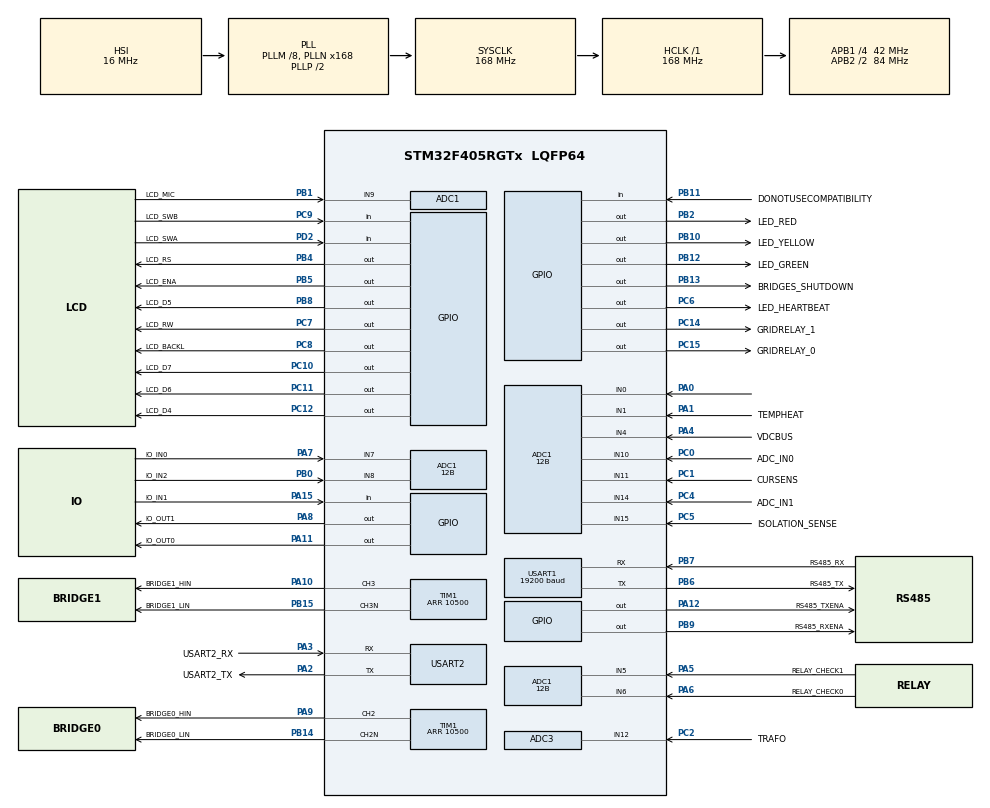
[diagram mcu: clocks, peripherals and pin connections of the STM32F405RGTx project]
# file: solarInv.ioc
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ADC1.Channel-0\#ChannelRegularConversion=ADC_CHANNEL_1
ADC1.Channel-3\#ChannelRegularConversion=ADC_CHANNEL_15
ADC1.Channel-4\#ChannelRegularConversion=ADC_CHANNEL_5
ADC1.Channel-5\#ChannelRegularConversion=ADC_CHANNEL_6
ADC1.Channel-8\#ChannelRegularConversion=ADC_CHANNEL_15
ADC1.Channel-9\#ChannelRegularConversion=ADC_CHANNEL_9
ADC1.ClockPrescaler=ADC_CLOCK_SYNC_PCLK_DIV4
ADC1.ContinuousConvMode=DISABLE
ADC1.DMAContinuousRequests=ENABLE
ADC1.DataAlign=ADC_DATAALIGN_RIGHT
ADC1.DiscontinuousConvMode=ENABLE
ADC1.EOCSelection=ADC_EOC_SEQ_CONV
ADC1.EnableAnalogWatchDog=false
ADC1.ExternalTrigConv=ADC_EXTERNALTRIGCONV_T1_CC1
ADC1.ExternalTrigConvEdge=ADC_EXTERNALTRIGCONVEDGE_RISING
ADC1.InjNumberOfConversion=0
ADC1.NbrOfConversion=5
ADC1.NbrOfConversionFlag=1
ADC1.NbrOfDiscConversion=1
ADC1.Rank-0\#ChannelRegularConversion=1
ADC1.Rank-3\#ChannelRegularConversion=4
ADC1.Rank-4\#ChannelRegularConversion=2
ADC1.Rank-5\#ChannelRegularConversion=3
ADC1.Rank-8\#ChannelRegularConversion=4
ADC1.Rank-9\#ChannelRegularConversion=5
ADC1.Resolution=ADC_RESOLUTION_12B
ADC1.SamplingTime-0\#ChannelRegularConversion=ADC_SAMPLETIME_3CYCLES
ADC1.SamplingTime-3\#ChannelRegularConversion=ADC_SAMPLETIME_3CYCLES
ADC1.SamplingTime-4\#ChannelRegularConversion=ADC_SAMPLETIME_3CYCLES
ADC1.SamplingTime-5\#ChannelRegularConversion=ADC_SAMPLETIME_3CYCLES
ADC1.SamplingTime-8\#ChannelRegularConversion=ADC_SAMPLETIME_3CYCLES
ADC1.SamplingTime-9\#ChannelRegularConversion=ADC_SAMPLETIME_3CYCLES
ADC1.ScanConvMode=ENABLE
ADC1.master=1
ADC2.Channel-0\#ChannelRegularConversion=ADC_CHANNEL_4
ADC2.Channel-1\#ChannelRegularConversion=ADC_CHANNEL_4
ADC2.ClockPrescaler=ADC_CLOCK_SYNC_PCLK_DIV4
ADC2.ContinuousConvMode=DISABLE
ADC2.DMAContinuousRequests=ENABLE
ADC2.DataAlign=ADC_DATAALIGN_RIGHT
ADC2.DiscontinuousConvMode=ENABLE
ADC2.EOCSelection=ADC_EOC_SEQ_CONV
ADC2.EnableAnalogWatchDog=false
ADC2.ExternalTrigConv=ADC_EXTERNALTRIGCONV_T1_CC1
ADC2.ExternalTrigConvEdge=ADC_EXTERNALTRIGCONVEDGE_RISING
ADC2.InjNumberOfConversion=0
ADC2.NbrOfConversion=2
ADC2.NbrOfConversionFlag=1
ADC2.NbrOfDiscConversion=1
ADC2.Rank-0\#ChannelRegularConversion=1
ADC2.Rank-1\#ChannelRegularConversion=2
ADC2.Resolution=ADC_RESOLUTION_12B
ADC2.SamplingTime-0\#ChannelRegularConversion=ADC_SAMPLETIME_3CYCLES
ADC2.SamplingTime-1\#ChannelRegularConversion=ADC_SAMPLETIME_3CYCLES
ADC2.ScanConvMode=ENABLE
ADC3.Channel-4\#ChannelRegularConversion=ADC_CHANNEL_11
ADC3.Channel-5\#ChannelRegularConversion=ADC_CHANNEL_12
ADC3.ContinuousConvMode=DISABLE
ADC3.DMAContinuousRequests=ENABLE
ADC3.DataAlign=ADC_DATAALIGN_RIGHT
ADC3.DiscontinuousConvMode=ENABLE
ADC3.EOCSelection=ADC_EOC_SINGLE_CONV
ADC3.EnableAnalogWatchDog=false
ADC3.ExternalTrigConv=ADC_EXTERNALTRIGCONV_T1_CC1
ADC3.ExternalTrigConvEdge=ADC_EXTERNALTRIGCONVEDGE_RISING
ADC3.InjNumberOfConversion=0
ADC3.NbrOfConversion=2
ADC3.NbrOfConversionFlag=1
ADC3.NbrOfDiscConversion=1
ADC3.Rank-4\#ChannelRegularConversion=1
ADC3.Rank-5\#ChannelRegularConversion=2
ADC3.Resolution=ADC_RESOLUTION_12B
ADC3.SamplingTime-4\#ChannelRegularConversion=ADC_SAMPLETIME_3CYCLES
ADC3.SamplingTime-5\#ChannelRegularConversion=ADC_SAMPLETIME_3CYCLES
ADC3.ScanConvMode=ENABLE
Dma.ADC1.4.Direction=DMA_PERIPH_TO_MEMORY
Dma.ADC1.4.FIFOMode=DMA_FIFOMODE_DISABLE
Dma.ADC1.4.Instance=DMA2_Stream0
Dma.ADC1.4.MemDataAlignment=DMA_MDATAALIGN_HALFWORD
Dma.ADC1.4.MemInc=DMA_MINC_ENABLE
Dma.ADC1.4.Mode=DMA_CIRCULAR
Dma.ADC1.4.PeriphDataAlignment=DMA_PDATAALIGN_HALFWORD
Dma.ADC1.4.PeriphInc=DMA_PINC_DISABLE
Dma.ADC1.4.Priority=DMA_PRIORITY_MEDIUM
Dma.ADC2.5.Direction=DMA_PERIPH_TO_MEMORY
Dma.ADC2.5.FIFOMode=DMA_FIFOMODE_DISABLE
Dma.ADC2.5.Instance=DMA2_Stream2
Dma.ADC2.5.MemDataAlignment=DMA_MDATAALIGN_HALFWORD
Dma.ADC2.5.MemInc=DMA_MINC_ENABLE
Dma.ADC2.5.Mode=DMA_CIRCULAR
Dma.ADC2.5.PeriphDataAlignment=DMA_PDATAALIGN_HALFWORD
Dma.ADC2.5.PeriphInc=DMA_PINC_DISABLE
Dma.ADC2.5.Priority=DMA_PRIORITY_MEDIUM
Dma.ADC3.1.Direction=DMA_PERIPH_TO_MEMORY
Dma.ADC3.1.FIFOMode=DMA_FIFOMODE_DISABLE
Dma.ADC3.1.Instance=DMA2_Stream1
Dma.ADC3.1.MemDataAlignment=DMA_MDATAALIGN_HALFWORD
Dma.ADC3.1.MemInc=DMA_MINC_ENABLE
Dma.ADC3.1.Mode=DMA_CIRCULAR
Dma.ADC3.1.PeriphDataAlignment=DMA_PDATAALIGN_HALFWORD
Dma.ADC3.1.PeriphInc=DMA_PINC_DISABLE
Dma.ADC3.1.Priority=DMA_PRIORITY_MEDIUM
Dma.MEMTOMEM.0.Direction=DMA_MEMORY_TO_MEMORY
Dma.MEMTOMEM.0.FIFOMode=DMA_FIFOMODE_ENABLE
Dma.MEMTOMEM.0.FIFOThreshold=DMA_FIFO_THRESHOLD_FULL
Dma.MEMTOMEM.0.Instance=DMA2_Stream4
Dma.MEMTOMEM.0.MemBurst=DMA_MBURST_SINGLE
Dma.MEMTOMEM.0.MemDataAlignment=DMA_MDATAALIGN_WORD
Dma.MEMTOMEM.0.MemInc=DMA_MINC_ENABLE
Dma.MEMTOMEM.0.Mode=DMA_NORMAL
Dma.MEMTOMEM.0.PeriphBurst=DMA_PBURST_SINGLE
Dma.MEMTOMEM.0.PeriphDataAlignment=DMA_PDATAALIGN_WORD
Dma.MEMTOMEM.0.PeriphInc=DMA_PINC_ENABLE
Dma.MEMTOMEM.0.Priority=DMA_PRIORITY_LOW
Dma.Request0=MEMTOMEM
Dma.Request1=ADC3
Dma.Request2=USART1_TX
Dma.Request3=USART1_RX
Dma.Request4=ADC1
Dma.Request5=ADC2
Dma.USART1_RX.3.Direction=DMA_PERIPH_TO_MEMORY
Dma.USART1_RX.3.FIFOMode=DMA_FIFOMODE_DISABLE
Dma.USART1_RX.3.Instance=DMA2_Stream5
Dma.USART1_RX.3.MemDataAlignment=DMA_MDATAALIGN_BYTE
Dma.USART1_RX.3.MemInc=DMA_MINC_ENABLE
Dma.USART1_RX.3.Mode=DMA_CIRCULAR
Dma.USART1_RX.3.PeriphDataAlignment=DMA_PDATAALIGN_BYTE
Dma.USART1_RX.3.PeriphInc=DMA_PINC_DISABLE
Dma.USART1_RX.3.Priority=DMA_PRIORITY_LOW
Dma.USART1_TX.2.Direction=DMA_MEMORY_TO_PERIPH
Dma.USART1_TX.2.FIFOMode=DMA_FIFOMODE_DISABLE
Dma.USART1_TX.2.Instance=DMA2_Stream7
Dma.USART1_TX.2.MemDataAlignment=DMA_MDATAALIGN_BYTE
Dma.USART1_TX.2.MemInc=DMA_MINC_ENABLE
Dma.USART1_TX.2.Mode=DMA_NORMAL
Dma.USART1_TX.2.PeriphDataAlignment=DMA_PDATAALIGN_BYTE
Dma.USART1_TX.2.PeriphInc=DMA_PINC_DISABLE
Dma.USART1_TX.2.Priority=DMA_PRIORITY_LOW
FREERTOS.INCLUDE_vTaskDelayUntil=1
FREERTOS.Tasks01=defaultTask,0,4192,StartDefaultTask,Default,NULL,Dynamic,NULL,NULL;commandThread,-2,4192,startCommandThread,As external,NULL,Dynamic,NULL,NULL
FREERTOS.configENABLE_BACKWARD_COMPATIBILITY=0
FREERTOS.configTOTAL_HEAP_SIZE=64000
FREERTOS.configUSE_COUNTING_SEMAPHORES=1
Mcu.Family=STM32F4
Mcu.Name=STM32F405RGTx
Mcu.Package=LQFP64
NVIC.DMA2_Stream0_IRQn=true\:5\:0\:false\:false\:true\:false\:true\:true
NVIC.DMA2_Stream1_IRQn=true\:5\:0\:true\:false\:true\:true\:true\:true
NVIC.DMA2_Stream2_IRQn=true\:5\:0\:false\:false\:true\:true\:true\:true
NVIC.DMA2_Stream4_IRQn=true\:5\:0\:false\:false\:true\:false\:true\:true
NVIC.DMA2_Stream5_IRQn=true\:5\:0\:false\:false\:true\:false\:true\:true
NVIC.DMA2_Stream7_IRQn=true\:5\:0\:true\:false\:true\:true\:true\:true
NVIC.FPU_IRQn=true\:5\:0\:false\:false\:true\:true\:false\:false
NVIC.PriorityGroup=NVIC_PRIORITYGROUP_4
NVIC.TIM8_UP_TIM13_IRQn=true\:0\:0\:false\:false\:true\:false\:true\:true
NVIC.TimeBase=TIM8_UP_TIM13_IRQn
NVIC.TimeBaseIP=TIM13
NVIC.USART1_IRQn=true\:5\:0\:true\:false\:true\:true\:true\:true
PA0-WKUP.Signal=ADCx_IN0
PA1.GPIO_Label=TEMPHEAT
PA1.Signal=ADCx_IN1
PA10.GPIO_Label=BRIDGE1_HIN
PA10.GPIO_Speed=GPIO_SPEED_FREQ_HIGH
PA10.Signal=S_TIM1_CH3
PA11.GPIO_Label=IO_OUT0
PA11.Signal=GPIO_Output
PA12.GPIO_Label=RS485_TXENA
PA12.Signal=GPIO_Output
PA13.Mode=Trace_Asynchronous_SW
PA13.Signal=SYS_JTMS-SWDIO
PA14.Mode=Trace_Asynchronous_SW
PA14.Signal=SYS_JTCK-SWCLK
PA15.GPIO_Label=IO_IN1
PA15.GPIO_PuPd=GPIO_NOPULL
PA15.Signal=GPIO_Input
PA2.GPIO_Label=USART2_TX
PA2.GPIO_Speed=GPIO_SPEED_FREQ_HIGH
PA2.Mode=Asynchronous
PA2.Signal=USART2_TX
PA3.GPIO_Label=USART2_RX
PA3.GPIO_Speed=GPIO_SPEED_FREQ_HIGH
PA3.Mode=Asynchronous
PA3.Signal=USART2_RX
PA4.GPIO_Label=VDCBUS
PA4.Signal=ADCx_IN4
PA5.GPIO_Label=RELAY_CHECK1
PA5.Signal=ADCx_IN5
PA6.GPIO_Label=RELAY_CHECK0
PA6.Signal=ADCx_IN6
PA7.GPIO_Label=IO_IN0
PA7.Signal=ADCx_IN7
PA8.GPIO_Label=IO_OUT1
PA8.Signal=GPIO_Output
PA9.GPIO_Label=BRIDGE0_HIN
PA9.GPIO_Speed=GPIO_SPEED_FREQ_HIGH
PA9.Signal=S_TIM1_CH2
PB0.GPIO_Label=IO_IN2
PB0.Signal=ADCx_IN8
PB1.GPIO_Label=LCD_MIC
PB1.Signal=ADCx_IN9
PB10.GPIO_Label=LED_YELLOW
PB10.Signal=GPIO_Output
PB11.GPIO_Label=DONOTUSECOMPATIBILITY
PB11.GPIO_Mode=GPIO_MODE_INPUT
PB11.GPIO_PuPd=GPIO_NOPULL
PB11.Signal=GPIO_Input
PB12.GPIO_Label=LED_GREEN
PB12.Signal=GPIO_Output
PB13.GPIO_Label=BRIDGES_SHUTDOWN
PB13.GPIO_Speed=GPIO_SPEED_FREQ_MEDIUM
PB13.PinState=GPIO_PIN_SET
PB13.Signal=GPIO_Output
PB14.GPIO_Label=BRIDGE0_LIN
PB14.GPIO_ModeDefaultPP=GPIO_MODE_AF_PP
PB14.GPIO_PuPd=GPIO_NOPULL
PB14.GPIO_Speed=GPIO_SPEED_FREQ_HIGH
PB14.Mode=PWM Generation2 CH2 CH2N
PB14.Signal=TIM1_CH2N
PB15.GPIO_Label=BRIDGE1_LIN
PB15.GPIO_ModeDefaultPP=GPIO_MODE_AF_PP
PB15.GPIO_PuPd=GPIO_NOPULL
PB15.GPIO_Speed=GPIO_SPEED_FREQ_HIGH
PB15.Mode=PWM Generation3 CH3 CH3N
PB15.Signal=TIM1_CH3N
PB2.GPIO_Label=LED_RED
PB2.Signal=GPIO_Output
PB3.Mode=Trace_Asynchronous_SW
PB3.Signal=SYS_JTDO-SWO
PB4.GPIO_Label=LCD_RS
PB4.Signal=GPIO_Output
PB5.GPIO_Label=LCD_ENA
PB5.GPIO_ModeDefaultOutputPP=GPIO_MODE_OUTPUT_PP
PB5.GPIO_PuPd=GPIO_NOPULL
PB5.GPIO_Speed=GPIO_SPEED_FREQ_LOW
PB5.PinState=GPIO_PIN_RESET
PB5.Signal=GPIO_Output
PB6.GPIO_Label=RS485_TX
PB6.GPIO_Speed=GPIO_SPEED_FREQ_HIGH
PB6.Mode=Asynchronous
PB6.Signal=USART1_TX
PB7.GPIO_Label=RS485_RX
PB7.GPIO_Speed=GPIO_SPEED_FREQ_HIGH
PB7.Mode=Asynchronous
PB7.Signal=USART1_RX
PB8.GPIO_Label=LCD_D5
PB8.Signal=GPIO_Output
PB9.GPIO_Label=RS485_RXENA
PB9.Signal=GPIO_Output
PC0.GPIO_Label=ADC_IN0
PC0.Signal=ADCx_IN10
PC1.GPIO_Label=CURSENS
PC1.GPIO_Mode=GPIO_MODE_ANALOG
PC1.GPIO_PuPd=GPIO_NOPULL
PC1.Signal=ADCx_IN11
PC10.GPIO_Label=LCD_D7
PC10.Signal=GPIO_Output
PC11.GPIO_Label=LCD_D6
PC11.Signal=GPIO_Output
PC12.GPIO_Label=LCD_D4
PC12.Signal=GPIO_Output
PC14-OSC32_IN.GPIO_Label=GRIDRELAY_1
PC14-OSC32_IN.Signal=GPIO_Output
PC15-OSC32_OUT.GPIO_Label=GRIDRELAY_0
PC15-OSC32_OUT.Signal=GPIO_Output
PC2.GPIO_Label=TRAFO
PC2.GPIO_Mode=GPIO_MODE_ANALOG
PC2.GPIO_PuPd=GPIO_NOPULL
PC2.Signal=ADCx_IN12
PC4.GPIO_Label=ADC_IN1
PC4.Signal=ADCx_IN14
PC5.GPIO_Label=ISOLATION_SENSE
PC5.Signal=ADCx_IN15
PC6.GPIO_Label=LED_HEARTBEAT
PC6.Signal=GPIO_Output
PC7.GPIO_Label=LCD_RW
PC7.Signal=GPIO_Output
PC8.GPIO_Label=LCD_BACKL
PC8.Signal=GPIO_Output
PC9.GPIO_Label=LCD_SWB
PC9.GPIO_PuPd=GPIO_PULLUP
PC9.Signal=GPIO_Input
PD2.GPIO_Label=LCD_SWA
PD2.GPIO_PuPd=GPIO_PULLUP
PD2.Signal=GPIO_Input
ProjectManager.HeapSize=0x400
ProjectManager.StackSize=0x800
ProjectManager.TargetToolchain=STM32CubeIDE
RCC.48MHZClocksFreq_Value=48000000
RCC.AHBFreq_Value=168000000
RCC.APB1CLKDivider=RCC_HCLK_DIV4
RCC.APB1Freq_Value=42000000
RCC.APB1TimFreq_Value=84000000
RCC.APB2CLKDivider=RCC_HCLK_DIV2
RCC.APB2Freq_Value=84000000
RCC.APB2TimFreq_Value=168000000
RCC.CortexFreq_Value=168000000
RCC.HCLKFreq_Value=168000000
RCC.HSE_VALUE=8000000
RCC.HSI_VALUE=16000000
RCC.LSE_VALUE=32768
RCC.PLLM=8
RCC.PLLN=168
RCC.PLLQ=7
RCC.SYSCLKFreq_VALUE=168000000
RCC.SYSCLKSource=RCC_SYSCLKSOURCE_PLLCLK
RCC.VCOOutputFreq_Value=336000000
SH.ADCx_IN0.0=ADC1_IN0,IN0
SH.ADCx_IN1.0=ADC1_IN1,IN1
SH.ADCx_IN10.0=ADC1_IN10,IN10
SH.ADCx_IN11.0=ADC1_IN11,IN11
SH.ADCx_IN11.1=ADC3_IN11,IN11
SH.ADCx_IN11.2=ADC2_IN11,IN11
SH.ADCx_IN12.0=ADC3_IN12,IN12
SH.ADCx_IN12.1=ADC1_IN12,IN12
SH.ADCx_IN12.2=ADC2_IN12,IN12
SH.ADCx_IN14.0=ADC1_IN14,IN14
SH.ADCx_IN15.0=ADC1_IN15,IN15
SH.ADCx_IN4.0=ADC1_IN4,IN4
SH.ADCx_IN4.1=ADC2_IN4,IN4
SH.ADCx_IN5.0=ADC1_IN5,IN5
SH.ADCx_IN6.0=ADC1_IN6,IN6
SH.ADCx_IN7.0=ADC1_IN7,IN7
SH.ADCx_IN8.0=ADC1_IN8,IN8
SH.ADCx_IN9.0=ADC1_IN9,IN9
SH.ADCx_IN9.1=ADC2_IN9,IN9
SH.S_TIM1_CH2.0=TIM1_CH2,PWM Generation2 CH2 CH2N
SH.S_TIM1_CH3.0=TIM1_CH3,PWM Generation3 CH3 CH3N
TIM1.AutomaticOutput=TIM_AUTOMATICOUTPUT_ENABLE
TIM1.BreakPolarity=TIM_BREAKPOLARITY_LOW
TIM1.BreakState=TIM_BREAK_DISABLE
TIM1.Channel-PWM\ Generation2\ CH2\ CH2N=TIM_CHANNEL_2
TIM1.Channel-PWM\ Generation3\ CH3\ CH3N=TIM_CHANNEL_3
TIM1.CounterMode=TIM_COUNTERMODE_UP
TIM1.DeadTime=30
TIM1.OCNPolarity_2=TIM_OCNPOLARITY_HIGH
TIM1.OCNPolarity_3=TIM_OCNPOLARITY_HIGH
TIM1.OffStateIDLEMode=TIM_OSSI_ENABLE
TIM1.OffStateRunMode=TIM_OSSR_ENABLE
TIM1.Period=10500
TIM2.AutoReloadPreload=TIM_AUTORELOAD_PRELOAD_ENABLE
TIM2.Period=16000
TIM2.Prescaler=5250
TIM4.AutoReloadPreload=TIM_AUTORELOAD_PRELOAD_DISABLE
TIM4.Period=3281
TIM4.Prescaler=1280
USART1.BaudRate=19200
USART1.VirtualMode=VM_ASYNC
USART2.VirtualMode=VM_ASYNC
VP_ADC1_Vref_Input.Mode=IN-Vrefint
VP_FREERTOS_VS_CMSIS_V1.Mode=CMSIS_V1
VP_SYS_VS_tim13.Mode=TIM13
VP_TIM1_VS_ClockSourceINT.Mode=Internal
VP_TIM2_VS_ClockSourceINT.Mode=Internal
VP_TIM4_VS_ClockSourceINT.Mode=Internal
board=solarInv

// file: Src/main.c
/* USER CODE BEGIN Header */
/**
  ******************************************************************************
  * @file           : main.c
  * @brief          : Main program body
  ******************************************************************************
  * @attention
  *
  * <h2><center>&copy; Copyright (c) 2022 STMicroelectronics.
  * All rights reserved.</center></h2>
  *
  * This software component is licensed by ST under Ultimate Liberty license
  * SLA0044, the "License"; You may not use this file except in compliance with
  * the License. You may obtain a copy of the License at:
  *                             www.st.com/SLA0044
  *
  ******************************************************************************
  */
/* USER CODE END Header */
#include "main.h"
#include "cmsis_os.h"

/* USER CODE BEGIN Includes */
#include "HardwareDefines.h"
#include "controlLoop.h"
/* USER CODE END Includes */

ADC_HandleTypeDef hadc1;
ADC_HandleTypeDef hadc2;
ADC_HandleTypeDef hadc3;
DMA_HandleTypeDef hdma_adc1;
DMA_HandleTypeDef hdma_adc2;
DMA_HandleTypeDef hdma_adc3;

TIM_HandleTypeDef htim1;
TIM_HandleTypeDef htim2;
TIM_HandleTypeDef htim4;

UART_HandleTypeDef huart1;
UART_HandleTypeDef huart2;
DMA_HandleTypeDef hdma_usart1_tx;
DMA_HandleTypeDef hdma_usart1_rx;

DMA_HandleTypeDef hdma_memtomem_dma2_stream4;
osThreadId defaultTaskHandle;
osThreadId commandThreadHandle;

void SystemClock_Config(void);
static void MX_GPIO_Init(void);
static void MX_DMA_Init(void);
static void MX_ADC1_Init(void);
static void MX_ADC2_Init(void);
static void MX_ADC3_Init(void);
static void MX_TIM1_Init(void);
static void MX_TIM4_Init(void);
static void MX_USART1_UART_Init(void);
static void MX_USART2_UART_Init(void);
static void MX_TIM2_Init(void);
void StartDefaultTask(void const * argument);
extern void startCommandThread(void const * argument);

int main(void)
{

  /* MCU Configuration--------------------------------------------------------*/

  /* Reset of all peripherals, Initializes the Flash interface and the Systick. */
  HAL_Init();

  /* Configure the system clock */
  SystemClock_Config();

  /* Initialize all configured peripherals */
  MX_GPIO_Init();
  MX_DMA_Init();
  MX_ADC1_Init();
  MX_ADC2_Init();
  MX_ADC3_Init();
  MX_TIM1_Init();
  MX_TIM4_Init();
  MX_USART1_UART_Init();
  MX_USART2_UART_Init();
  MX_TIM2_Init();

  /* Create the thread(s) */
  /* definition and creation of defaultTask */
  osThreadDef(defaultTask, StartDefaultTask, osPriorityNormal, 0, 4192);
  defaultTaskHandle = osThreadCreate(osThread(defaultTask), NULL);

  /* definition and creation of commandThread */
  osThreadDef(commandThread, startCommandThread, osPriorityLow, 0, 4192);
  commandThreadHandle = osThreadCreate(osThread(commandThread), NULL);

  /* Start scheduler */
  osKernelStart();

  /* We should never get here as control is now taken by the scheduler */
  /* Infinite loop */
  while (1)
  {

  }
}

void SystemClock_Config(void)
{
  RCC_OscInitTypeDef RCC_OscInitStruct = {0};
  RCC_ClkInitTypeDef RCC_ClkInitStruct = {0};

  /** Configure the main internal regulator output voltage
  */
  __HAL_RCC_PWR_CLK_ENABLE();
  __HAL_PWR_VOLTAGESCALING_CONFIG(PWR_REGULATOR_VOLTAGE_SCALE1);
  /** Initializes the RCC Oscillators according to the specified parameters
  * in the RCC_OscInitTypeDef structure.
  */
  RCC_OscInitStruct.OscillatorType = RCC_OSCILLATORTYPE_HSI;
  RCC_OscInitStruct.HSIState = RCC_HSI_ON;
  RCC_OscInitStruct.HSICalibrationValue = RCC_HSICALIBRATION_DEFAULT;
  RCC_OscInitStruct.PLL.PLLState = RCC_PLL_ON;
  RCC_OscInitStruct.PLL.PLLSource = RCC_PLLSOURCE_HSI;
  RCC_OscInitStruct.PLL.PLLM = 8;
  RCC_OscInitStruct.PLL.PLLN = 168;
  RCC_OscInitStruct.PLL.PLLP = RCC_PLLP_DIV2;
  RCC_OscInitStruct.PLL.PLLQ = 7;
  if (HAL_RCC_OscConfig(&RCC_OscInitStruct) != HAL_OK)
  {
    Error_Handler();
  }
  /** Initializes the CPU, AHB and APB buses clocks
  */
  RCC_ClkInitStruct.ClockType = RCC_CLOCKTYPE_HCLK|RCC_CLOCKTYPE_SYSCLK
                              |RCC_CLOCKTYPE_PCLK1|RCC_CLOCKTYPE_PCLK2;
  RCC_ClkInitStruct.SYSCLKSource = RCC_SYSCLKSOURCE_PLLCLK;
  RCC_ClkInitStruct.AHBCLKDivider = RCC_SYSCLK_DIV1;
  RCC_ClkInitStruct.APB1CLKDivider = RCC_HCLK_DIV4;
  RCC_ClkInitStruct.APB2CLKDivider = RCC_HCLK_DIV2;

  if (HAL_RCC_ClockConfig(&RCC_ClkInitStruct, FLASH_LATENCY_5) != HAL_OK)
  {
    Error_Handler();
  }
}

static void MX_ADC1_Init(void)
{

  ADC_ChannelConfTypeDef sConfig = {0};

  /** Configure the global features of the ADC (Clock, Resolution, Data Alignment and number of conversion)
  */
  hadc1.Instance = ADC1;
  hadc1.Init.ClockPrescaler = ADC_CLOCK_SYNC_PCLK_DIV4;
  hadc1.Init.Resolution = ADC_RESOLUTION_12B;
  hadc1.Init.ScanConvMode = ENABLE;
  hadc1.Init.ContinuousConvMode = DISABLE;
  hadc1.Init.DiscontinuousConvMode = ENABLE;
  hadc1.Init.NbrOfDiscConversion = 1;
  hadc1.Init.ExternalTrigConvEdge = ADC_EXTERNALTRIGCONVEDGE_RISING;
  hadc1.Init.ExternalTrigConv = ADC_EXTERNALTRIGCONV_T1_CC1;
  hadc1.Init.DataAlign = ADC_DATAALIGN_RIGHT;
  hadc1.Init.NbrOfConversion = 5;
  hadc1.Init.DMAContinuousRequests = ENABLE;
  hadc1.Init.EOCSelection = ADC_EOC_SEQ_CONV;
  if (HAL_ADC_Init(&hadc1) != HAL_OK)
  {
    Error_Handler();
  }
  /** Configure for the selected ADC regular channel its corresponding rank in the sequencer and its sample time.
  */
  sConfig.Channel = ADC_CHANNEL_1;
  sConfig.Rank = 1;
  sConfig.SamplingTime = ADC_SAMPLETIME_3CYCLES;
  if (HAL_ADC_ConfigChannel(&hadc1, &sConfig) != HAL_OK)
  {
    Error_Handler();
  }
  /** Configure for the selected ADC regular channel its corresponding rank in the sequencer and its sample time.
  */
  sConfig.Channel = ADC_CHANNEL_15;
  sConfig.Rank = 4;
  if (HAL_ADC_ConfigChannel(&hadc1, &sConfig) != HAL_OK)
  {
    Error_Handler();
  }
  /** Configure for the selected ADC regular channel its corresponding rank in the sequencer and its sample time.
  */
  sConfig.Channel = ADC_CHANNEL_5;
  sConfig.Rank = 2;
  if (HAL_ADC_ConfigChannel(&hadc1, &sConfig) != HAL_OK)
  {
    Error_Handler();
  }
  /** Configure for the selected ADC regular channel its corresponding rank in the sequencer and its sample time.
  */
  sConfig.Channel = ADC_CHANNEL_6;
  sConfig.Rank = 3;
  if (HAL_ADC_ConfigChannel(&hadc1, &sConfig) != HAL_OK)
  {
    Error_Handler();
  }
  /** Configure for the selected ADC regular channel its corresponding rank in the sequencer and its sample time.
  */
  sConfig.Channel = ADC_CHANNEL_9;
  sConfig.Rank = 5;
  if (HAL_ADC_ConfigChannel(&hadc1, &sConfig) != HAL_OK)
  {
    Error_Handler();
  }

}

static void MX_ADC2_Init(void)
{

  ADC_ChannelConfTypeDef sConfig = {0};

  /** Configure the global features of the ADC (Clock, Resolution, Data Alignment and number of conversion)
  */
  hadc2.Instance = ADC2;
  hadc2.Init.ClockPrescaler = ADC_CLOCK_SYNC_PCLK_DIV4;
  hadc2.Init.Resolution = ADC_RESOLUTION_12B;
  hadc2.Init.ScanConvMode = ENABLE;
  hadc2.Init.ContinuousConvMode = DISABLE;
  hadc2.Init.DiscontinuousConvMode = ENABLE;
  hadc2.Init.NbrOfDiscConversion = 1;
  hadc2.Init.ExternalTrigConvEdge = ADC_EXTERNALTRIGCONVEDGE_RISING;
  hadc2.Init.ExternalTrigConv = ADC_EXTERNALTRIGCONV_T1_CC1;
  hadc2.Init.DataAlign = ADC_DATAALIGN_RIGHT;
  hadc2.Init.NbrOfConversion = 2;
  hadc2.Init.DMAContinuousRequests = ENABLE;
  hadc2.Init.EOCSelection = ADC_EOC_SEQ_CONV;
  if (HAL_ADC_Init(&hadc2) != HAL_OK)
  {
    Error_Handler();
  }
  /** Configure for the selected ADC regular channel its corresponding rank in the sequencer and its sample time.
  */
  sConfig.Channel = ADC_CHANNEL_4;
  sConfig.Rank = 1;
  sConfig.SamplingTime = ADC_SAMPLETIME_3CYCLES;
  if (HAL_ADC_ConfigChannel(&hadc2, &sConfig) != HAL_OK)
  {
    Error_Handler();
  }
  /** Configure for the selected ADC regular channel its corresponding rank in the sequencer and its sample time.
  */
  sConfig.Rank = 2;
  if (HAL_ADC_ConfigChannel(&hadc2, &sConfig) != HAL_OK)
  {
    Error_Handler();
  }

}

static void MX_ADC3_Init(void)
{

  ADC_ChannelConfTypeDef sConfig = {0};

  /** Configure the global features of the ADC (Clock, Resolution, Data Alignment and number of conversion)
  */
  hadc3.Instance = ADC3;
  hadc3.Init.ClockPrescaler = ADC_CLOCK_SYNC_PCLK_DIV4;
  hadc3.Init.Resolution = ADC_RESOLUTION_12B;
  hadc3.Init.ScanConvMode = ENABLE;
  hadc3.Init.ContinuousConvMode = DISABLE;
  hadc3.Init.DiscontinuousConvMode = ENABLE;
  hadc3.Init.NbrOfDiscConversion = 1;
  hadc3.Init.ExternalTrigConvEdge = ADC_EXTERNALTRIGCONVEDGE_RISING;
  hadc3.Init.ExternalTrigConv = ADC_EXTERNALTRIGCONV_T1_CC1;
  hadc3.Init.DataAlign = ADC_DATAALIGN_RIGHT;
  hadc3.Init.NbrOfConversion = 2;
  hadc3.Init.DMAContinuousRequests = ENABLE;
  hadc3.Init.EOCSelection = ADC_EOC_SINGLE_CONV;
  if (HAL_ADC_Init(&hadc3) != HAL_OK)
  {
    Error_Handler();
  }
  /** Configure for the selected ADC regular channel its corresponding rank in the sequencer and its sample time.
  */
  sConfig.Channel = ADC_CHANNEL_11;
  sConfig.Rank = 1;
  sConfig.SamplingTime = ADC_SAMPLETIME_3CYCLES;
  if (HAL_ADC_ConfigChannel(&hadc3, &sConfig) != HAL_OK)
  {
    Error_Handler();
  }
  /** Configure for the selected ADC regular channel its corresponding rank in the sequencer and its sample time.
  */
  sConfig.Channel = ADC_CHANNEL_12;
  sConfig.Rank = 2;
  if (HAL_ADC_ConfigChannel(&hadc3, &sConfig) != HAL_OK)
  {
    Error_Handler();
  }

}

static void MX_TIM1_Init(void)
{

  TIM_ClockConfigTypeDef sClockSourceConfig = {0};
  TIM_MasterConfigTypeDef sMasterConfig = {0};
  TIM_OC_InitTypeDef sConfigOC = {0};
  TIM_BreakDeadTimeConfigTypeDef sBreakDeadTimeConfig = {0};

  htim1.Instance = TIM1;
  htim1.Init.Prescaler = 0;
  htim1.Init.CounterMode = TIM_COUNTERMODE_UP;
  htim1.Init.Period = 10500;
  htim1.Init.ClockDivision = TIM_CLOCKDIVISION_DIV1;
  htim1.Init.RepetitionCounter = 0;
  htim1.Init.AutoReloadPreload = TIM_AUTORELOAD_PRELOAD_DISABLE;
  if (HAL_TIM_Base_Init(&htim1) != HAL_OK)
  {
    Error_Handler();
  }
  sClockSourceConfig.ClockSource = TIM_CLOCKSOURCE_INTERNAL;
  if (HAL_TIM_ConfigClockSource(&htim1, &sClockSourceConfig) != HAL_OK)
  {
    Error_Handler();
  }
  if (HAL_TIM_PWM_Init(&htim1) != HAL_OK)
  {
    Error_Handler();
  }
  sMasterConfig.MasterOutputTrigger = TIM_TRGO_RESET;
  sMasterConfig.MasterSlaveMode = TIM_MASTERSLAVEMODE_DISABLE;
  if (HAL_TIMEx_MasterConfigSynchronization(&htim1, &sMasterConfig) != HAL_OK)
  {
    Error_Handler();
  }
  sConfigOC.OCMode = TIM_OCMODE_PWM1;
  sConfigOC.Pulse = 0;
  sConfigOC.OCPolarity = TIM_OCPOLARITY_HIGH;
  sConfigOC.OCNPolarity = TIM_OCNPOLARITY_HIGH;
  sConfigOC.OCFastMode = TIM_OCFAST_DISABLE;
  sConfigOC.OCIdleState = TIM_OCIDLESTATE_RESET;
  sConfigOC.OCNIdleState = TIM_OCNIDLESTATE_RESET;
  if (HAL_TIM_PWM_ConfigChannel(&htim1, &sConfigOC, TIM_CHANNEL_2) != HAL_OK)
  {
    Error_Handler();
  }
  if (HAL_TIM_PWM_ConfigChannel(&htim1, &sConfigOC, TIM_CHANNEL_3) != HAL_OK)
  {
    Error_Handler();
  }
  sBreakDeadTimeConfig.OffStateRunMode = TIM_OSSR_ENABLE;
  sBreakDeadTimeConfig.OffStateIDLEMode = TIM_OSSI_ENABLE;
  sBreakDeadTimeConfig.LockLevel = TIM_LOCKLEVEL_OFF;
  sBreakDeadTimeConfig.DeadTime = 0;
  sBreakDeadTimeConfig.BreakState = TIM_BREAK_DISABLE;
  sBreakDeadTimeConfig.BreakPolarity = TIM_BREAKPOLARITY_LOW;
  sBreakDeadTimeConfig.AutomaticOutput = TIM_AUTOMATICOUTPUT_ENABLE;
  if (HAL_TIMEx_ConfigBreakDeadTime(&htim1, &sBreakDeadTimeConfig) != HAL_OK)
  {
    Error_Handler();
  }
  HAL_TIM_MspPostInit(&htim1);

}

static void MX_TIM2_Init(void)
{

  TIM_ClockConfigTypeDef sClockSourceConfig = {0};
  TIM_MasterConfigTypeDef sMasterConfig = {0};

  htim2.Instance = TIM2;
  htim2.Init.Prescaler = 5250;
  htim2.Init.CounterMode = TIM_COUNTERMODE_UP;
  htim2.Init.Period = 16000;
  htim2.Init.ClockDivision = TIM_CLOCKDIVISION_DIV1;
  htim2.Init.AutoReloadPreload = TIM_AUTORELOAD_PRELOAD_ENABLE;
  if (HAL_TIM_Base_Init(&htim2) != HAL_OK)
  {
    Error_Handler();
  }
  sClockSourceConfig.ClockSource = TIM_CLOCKSOURCE_INTERNAL;
  if (HAL_TIM_ConfigClockSource(&htim2, &sClockSourceConfig) != HAL_OK)
  {
    Error_Handler();
  }
  sMasterConfig.MasterOutputTrigger = TIM_TRGO_RESET;
  sMasterConfig.MasterSlaveMode = TIM_MASTERSLAVEMODE_DISABLE;
  if (HAL_TIMEx_MasterConfigSynchronization(&htim2, &sMasterConfig) != HAL_OK)
  {
    Error_Handler();
  }

}

static void MX_TIM4_Init(void)
{

  TIM_ClockConfigTypeDef sClockSourceConfig = {0};
  TIM_MasterConfigTypeDef sMasterConfig = {0};

  htim4.Instance = TIM4;
  htim4.Init.Prescaler = 1280;
  htim4.Init.CounterMode = TIM_COUNTERMODE_UP;
  htim4.Init.Period = 3281;
  htim4.Init.ClockDivision = TIM_CLOCKDIVISION_DIV1;
  htim4.Init.AutoReloadPreload = TIM_AUTORELOAD_PRELOAD_DISABLE;
  if (HAL_TIM_Base_Init(&htim4) != HAL_OK)
  {
    Error_Handler();
  }
  sClockSourceConfig.ClockSource = TIM_CLOCKSOURCE_INTERNAL;
  if (HAL_TIM_ConfigClockSource(&htim4, &sClockSourceConfig) != HAL_OK)
  {
    Error_Handler();
  }
  sMasterConfig.MasterOutputTrigger = TIM_TRGO_RESET;
  sMasterConfig.MasterSlaveMode = TIM_MASTERSLAVEMODE_DISABLE;
  if (HAL_TIMEx_MasterConfigSynchronization(&htim4, &sMasterConfig) != HAL_OK)
  {
    Error_Handler();
  }

}

static void MX_USART1_UART_Init(void)
{

  huart1.Instance = USART1;
  huart1.Init.BaudRate = 19200;
  huart1.Init.WordLength = UART_WORDLENGTH_8B;
  huart1.Init.StopBits = UART_STOPBITS_1;
  huart1.Init.Parity = UART_PARITY_NONE;
  huart1.Init.Mode = UART_MODE_TX_RX;
  huart1.Init.HwFlowCtl = UART_HWCONTROL_NONE;
  huart1.Init.OverSampling = UART_OVERSAMPLING_16;
  if (HAL_UART_Init(&huart1) != HAL_OK)
  {
    Error_Handler();
  }

}

static void MX_USART2_UART_Init(void)
{

  huart2.Instance = USART2;
  huart2.Init.BaudRate = 115200;
  huart2.Init.WordLength = UART_WORDLENGTH_8B;
  huart2.Init.StopBits = UART_STOPBITS_1;
  huart2.Init.Parity = UART_PARITY_NONE;
  huart2.Init.Mode = UART_MODE_TX_RX;
  huart2.Init.HwFlowCtl = UART_HWCONTROL_NONE;
  huart2.Init.OverSampling = UART_OVERSAMPLING_16;
  if (HAL_UART_Init(&huart2) != HAL_OK)
  {
    Error_Handler();
  }

}

static void MX_DMA_Init(void)
{

  /* DMA controller clock enable */
  __HAL_RCC_DMA2_CLK_ENABLE();

  /* Configure DMA request hdma_memtomem_dma2_stream4 on DMA2_Stream4 */
  hdma_memtomem_dma2_stream4.Instance = DMA2_Stream4;
  hdma_memtomem_dma2_stream4.Init.Channel = DMA_CHANNEL_0;
  hdma_memtomem_dma2_stream4.Init.Direction = DMA_MEMORY_TO_MEMORY;
  hdma_memtomem_dma2_stream4.Init.PeriphInc = DMA_PINC_ENABLE;
  hdma_memtomem_dma2_stream4.Init.MemInc = DMA_MINC_ENABLE;
  hdma_memtomem_dma2_stream4.Init.PeriphDataAlignment = DMA_PDATAALIGN_WORD;
  hdma_memtomem_dma2_stream4.Init.MemDataAlignment = DMA_MDATAALIGN_WORD;
  hdma_memtomem_dma2_stream4.Init.Mode = DMA_NORMAL;
  hdma_memtomem_dma2_stream4.Init.Priority = DMA_PRIORITY_LOW;
  hdma_memtomem_dma2_stream4.Init.FIFOMode = DMA_FIFOMODE_ENABLE;
  hdma_memtomem_dma2_stream4.Init.FIFOThreshold = DMA_FIFO_THRESHOLD_FULL;
  hdma_memtomem_dma2_stream4.Init.MemBurst = DMA_MBURST_SINGLE;
  hdma_memtomem_dma2_stream4.Init.PeriphBurst = DMA_PBURST_SINGLE;
  if (HAL_DMA_Init(&hdma_memtomem_dma2_stream4) != HAL_OK)
  {
    Error_Handler( );
  }

  /* DMA interrupt init */
  /* DMA2_Stream0_IRQn interrupt configuration */
  HAL_NVIC_SetPriority(DMA2_Stream0_IRQn, 5, 0);
  HAL_NVIC_EnableIRQ(DMA2_Stream0_IRQn);
  /* DMA2_Stream1_IRQn interrupt configuration */
  HAL_NVIC_SetPriority(DMA2_Stream1_IRQn, 5, 0);
  HAL_NVIC_EnableIRQ(DMA2_Stream1_IRQn);
  /* DMA2_Stream2_IRQn interrupt configuration */
  HAL_NVIC_SetPriority(DMA2_Stream2_IRQn, 5, 0);
  HAL_NVIC_EnableIRQ(DMA2_Stream2_IRQn);
  /* DMA2_Stream4_IRQn interrupt configuration */
  HAL_NVIC_SetPriority(DMA2_Stream4_IRQn, 5, 0);
  HAL_NVIC_EnableIRQ(DMA2_Stream4_IRQn);
  /* DMA2_Stream5_IRQn interrupt configuration */
  HAL_NVIC_SetPriority(DMA2_Stream5_IRQn, 5, 0);
  HAL_NVIC_EnableIRQ(DMA2_Stream5_IRQn);
  /* DMA2_Stream7_IRQn interrupt configuration */
  HAL_NVIC_SetPriority(DMA2_Stream7_IRQn, 5, 0);
  HAL_NVIC_EnableIRQ(DMA2_Stream7_IRQn);

}

static void MX_GPIO_Init(void)
{
  GPIO_InitTypeDef GPIO_InitStruct = {0};

  /* GPIO Ports Clock Enable */
  __HAL_RCC_GPIOC_CLK_ENABLE();
  __HAL_RCC_GPIOA_CLK_ENABLE();
  __HAL_RCC_GPIOB_CLK_ENABLE();
  __HAL_RCC_GPIOD_CLK_ENABLE();

  /*Configure GPIO pin Output Level */
  HAL_GPIO_WritePin(GPIOC, GRIDRELAY_1_Pin|GRIDRELAY_0_Pin|LED_HEARTBEAT_Pin|LCD_RW_Pin
                          |LCD_BACKL_Pin|LCD_D7_Pin|LCD_D6_Pin|LCD_D4_Pin, GPIO_PIN_RESET);

  /*Configure GPIO pin Output Level */
  HAL_GPIO_WritePin(GPIOB, LED_RED_Pin|LED_YELLOW_Pin|LED_GREEN_Pin|LCD_RS_Pin
                          |LCD_ENA_Pin|LCD_D5_Pin|RS485_RXENA_Pin, GPIO_PIN_RESET);

  /*Configure GPIO pin Output Level */
  HAL_GPIO_WritePin(BRIDGES_SHUTDOWN_GPIO_Port, BRIDGES_SHUTDOWN_Pin, GPIO_PIN_SET);

  /*Configure GPIO pin Output Level */
  HAL_GPIO_WritePin(GPIOA, IO_OUT1_Pin|IO_OUT0_Pin|RS485_TXENA_Pin, GPIO_PIN_RESET);

  /*Configure GPIO pins : GRIDRELAY_1_Pin GRIDRELAY_0_Pin LED_HEARTBEAT_Pin LCD_RW_Pin
                           LCD_BACKL_Pin LCD_D7_Pin LCD_D6_Pin LCD_D4_Pin */
  GPIO_InitStruct.Pin = GRIDRELAY_1_Pin|GRIDRELAY_0_Pin|LED_HEARTBEAT_Pin|LCD_RW_Pin
                          |LCD_BACKL_Pin|LCD_D7_Pin|LCD_D6_Pin|LCD_D4_Pin;
  GPIO_InitStruct.Mode = GPIO_MODE_OUTPUT_PP;
  GPIO_InitStruct.Pull = GPIO_NOPULL;
  GPIO_InitStruct.Speed = GPIO_SPEED_FREQ_LOW;
  HAL_GPIO_Init(GPIOC, &GPIO_InitStruct);

  /*Configure GPIO pins : LED_RED_Pin LED_YELLOW_Pin LED_GREEN_Pin LCD_RS_Pin
                           LCD_ENA_Pin LCD_D5_Pin RS485_RXENA_Pin */
  GPIO_InitStruct.Pin = LED_RED_Pin|LED_YELLOW_Pin|LED_GREEN_Pin|LCD_RS_Pin
                          |LCD_ENA_Pin|LCD_D5_Pin|RS485_RXENA_Pin;
  GPIO_InitStruct.Mode = GPIO_MODE_OUTPUT_PP;
  GPIO_InitStruct.Pull = GPIO_NOPULL;
  GPIO_InitStruct.Speed = GPIO_SPEED_FREQ_LOW;
  HAL_GPIO_Init(GPIOB, &GPIO_InitStruct);

  /*Configure GPIO pin : DONOTUSECOMPATIBILITY_Pin */
  GPIO_InitStruct.Pin = DONOTUSECOMPATIBILITY_Pin;
  GPIO_InitStruct.Mode = GPIO_MODE_INPUT;
  GPIO_InitStruct.Pull = GPIO_NOPULL;
  HAL_GPIO_Init(DONOTUSECOMPATIBILITY_GPIO_Port, &GPIO_InitStruct);

  /*Configure GPIO pin : BRIDGES_SHUTDOWN_Pin */
  GPIO_InitStruct.Pin = BRIDGES_SHUTDOWN_Pin;
  GPIO_InitStruct.Mode = GPIO_MODE_OUTPUT_PP;
  GPIO_InitStruct.Pull = GPIO_NOPULL;
  GPIO_InitStruct.Speed = GPIO_SPEED_FREQ_MEDIUM;
  HAL_GPIO_Init(BRIDGES_SHUTDOWN_GPIO_Port, &GPIO_InitStruct);

  /*Configure GPIO pin : LCD_SWB_Pin */
  GPIO_InitStruct.Pin = LCD_SWB_Pin;
  GPIO_InitStruct.Mode = GPIO_MODE_INPUT;
  GPIO_InitStruct.Pull = GPIO_PULLUP;
  HAL_GPIO_Init(LCD_SWB_GPIO_Port, &GPIO_InitStruct);

  /*Configure GPIO pins : IO_OUT1_Pin IO_OUT0_Pin RS485_TXENA_Pin */
  GPIO_InitStruct.Pin = IO_OUT1_Pin|IO_OUT0_Pin|RS485_TXENA_Pin;
  GPIO_InitStruct.Mode = GPIO_MODE_OUTPUT_PP;
  GPIO_InitStruct.Pull = GPIO_NOPULL;
  GPIO_InitStruct.Speed = GPIO_SPEED_FREQ_LOW;
  HAL_GPIO_Init(GPIOA, &GPIO_InitStruct);

  /*Configure GPIO pin : IO_IN1_Pin */
  GPIO_InitStruct.Pin = IO_IN1_Pin;
  GPIO_InitStruct.Mode = GPIO_MODE_INPUT;
  GPIO_InitStruct.Pull = GPIO_NOPULL;
  HAL_GPIO_Init(IO_IN1_GPIO_Port, &GPIO_InitStruct);

  /*Configure GPIO pin : LCD_SWA_Pin */
  GPIO_InitStruct.Pin = LCD_SWA_Pin;
  GPIO_InitStruct.Mode = GPIO_MODE_INPUT;
  GPIO_InitStruct.Pull = GPIO_PULLUP;
  HAL_GPIO_Init(LCD_SWA_GPIO_Port, &GPIO_InitStruct);

}

void StartDefaultTask(void const * argument)
{
  for(;;)
  {
    osDelay(1);
  }
}

 /**
  * @brief  Period elapsed callback in non blocking mode
  * @note   This function is called  when TIM13 interrupt took place, inside
  * HAL_TIM_IRQHandler(). It makes a direct call to HAL_IncTick() to increment
  * a global variable "uwTick" used as application time base.
  * @param  htim : TIM handle
  * @retval None
  */
void HAL_TIM_PeriodElapsedCallback(TIM_HandleTypeDef *htim)
{
  if (htim->Instance == TIM13) {
    HAL_IncTick();
  }
}

void Error_Handler(void)
{
  __disable_irq();
  while (1)
  {
  }
}

/************************ (C) COPYRIGHT STMicroelectronics *****END OF FILE****/
